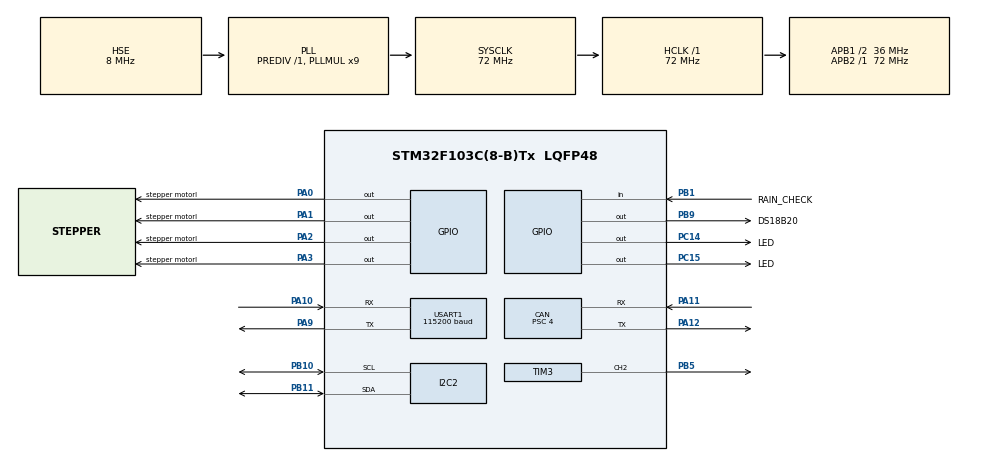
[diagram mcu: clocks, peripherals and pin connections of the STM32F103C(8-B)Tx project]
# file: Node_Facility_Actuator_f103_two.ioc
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CAN.BS1=CAN_BS1_7TQ
CAN.BS2=CAN_BS2_5TQ
CAN.CalculateBaudRate=692307
CAN.CalculateTimeBit=1444
CAN.CalculateTimeQuantum=111.11111111111111
CAN.Prescaler=4
CAN.SJW=CAN_SJW_2TQ
Dma.Request0=USART1_RX
Dma.USART1_RX.0.Direction=DMA_PERIPH_TO_MEMORY
Dma.USART1_RX.0.Instance=DMA1_Channel5
Dma.USART1_RX.0.MemDataAlignment=DMA_MDATAALIGN_BYTE
Dma.USART1_RX.0.MemInc=DMA_MINC_ENABLE
Dma.USART1_RX.0.Mode=DMA_CIRCULAR
Dma.USART1_RX.0.PeriphDataAlignment=DMA_PDATAALIGN_BYTE
Dma.USART1_RX.0.PeriphInc=DMA_PINC_DISABLE
Dma.USART1_RX.0.Priority=DMA_PRIORITY_LOW
FREERTOS.Queues01=Button_Queue,8,uint8_t,0,Dynamic,NULL,NULL
FREERTOS.Tasks01=APP_TASK,40,256,App_Show_Task,As weak,NULL,Dynamic,NULL,NULL;Acquire_Task,8,256,Data_Acquire_Task,As weak,NULL,Dynamic,NULL,NULL;Data_handle,8,256,Deal_data,As weak,NULL,Dynamic,NULL,NULL;Device,8,256,device_control,As weak,NULL,Dynamic,NULL,NULL
FREERTOS.configMINIMAL_STACK_SIZE=256
FREERTOS.configTOTAL_HEAP_SIZE=8192
Mcu.Family=STM32F1
Mcu.Name=STM32F103C(8-B)Tx
Mcu.Package=LQFP48
NVIC.DMA1_Channel5_IRQn=true\:5\:0\:false\:false\:true\:true\:false\:true\:true
NVIC.PriorityGroup=NVIC_PRIORITYGROUP_4
NVIC.TIM4_IRQn=true\:15\:0\:false\:false\:true\:false\:false\:true\:true
NVIC.TimeBase=TIM4_IRQn
NVIC.TimeBaseIP=TIM4
NVIC.USART1_IRQn=true\:5\:0\:false\:false\:false\:true\:true\:true\:true
PA0-WKUP.GPIO_Label=stepper motorl
PA0-WKUP.GPIO_ModeDefaultOutputPP=GPIO_MODE_OUTPUT_PP
PA0-WKUP.GPIO_PuPd=GPIO_NOPULL
PA0-WKUP.GPIO_Speed=GPIO_SPEED_FREQ_MEDIUM
PA0-WKUP.PinState=GPIO_PIN_RESET
PA0-WKUP.Signal=GPIO_Output
PA1.GPIO_Label=stepper motorl
PA1.GPIO_ModeDefaultOutputPP=GPIO_MODE_OUTPUT_PP
PA1.GPIO_PuPd=GPIO_NOPULL
PA1.GPIO_Speed=GPIO_SPEED_FREQ_MEDIUM
PA1.PinState=GPIO_PIN_RESET
PA1.Signal=GPIO_Output
PA10.Mode=Asynchronous
PA10.Signal=USART1_RX
PA11.Mode=CAN_Activate
PA11.Signal=CAN_RX
PA12.Mode=CAN_Activate
PA12.Signal=CAN_TX
PA13.Mode=Serial_Wire
PA13.Signal=SYS_JTMS-SWDIO
PA14.Mode=Serial_Wire
PA14.Signal=SYS_JTCK-SWCLK
PA2.GPIO_Label=stepper motorl
PA2.GPIO_ModeDefaultOutputPP=GPIO_MODE_OUTPUT_PP
PA2.GPIO_PuPd=GPIO_NOPULL
PA2.GPIO_Speed=GPIO_SPEED_FREQ_MEDIUM
PA2.PinState=GPIO_PIN_RESET
PA2.Signal=GPIO_Output
PA3.GPIO_Label=stepper motorl
PA3.GPIO_ModeDefaultOutputPP=GPIO_MODE_OUTPUT_PP
PA3.GPIO_PuPd=GPIO_NOPULL
PA3.GPIO_Speed=GPIO_SPEED_FREQ_MEDIUM
PA3.PinState=GPIO_PIN_RESET
PA3.Signal=GPIO_Output
PA9.Mode=Asynchronous
PA9.Signal=USART1_TX
PB1.GPIO_Label=RAIN_CHECK
PB1.Signal=GPIO_Input
PB10.Mode=I2C
PB10.Signal=I2C2_SCL
PB11.Mode=I2C
PB11.Signal=I2C2_SDA
PB5.Signal=S_TIM3_CH2
PB9.GPIO_Label=DS18B20
PB9.GPIO_ModeDefaultOutputPP=GPIO_MODE_OUTPUT_OD
PB9.GPIO_PuPd=GPIO_NOPULL
PB9.GPIO_Speed=GPIO_SPEED_FREQ_HIGH
PB9.Signal=GPIO_Output
PC14-OSC32_IN.GPIO_Label=LED
PC14-OSC32_IN.GPIO_ModeDefaultOutputPP=GPIO_MODE_OUTPUT_PP
PC14-OSC32_IN.GPIO_PuPd=GPIO_NOPULL
PC14-OSC32_IN.GPIO_Speed=GPIO_SPEED_FREQ_LOW
PC14-OSC32_IN.PinState=GPIO_PIN_SET
PC14-OSC32_IN.Signal=GPIO_Output
PC15-OSC32_OUT.GPIO_Label=LED
PC15-OSC32_OUT.GPIO_ModeDefaultOutputPP=GPIO_MODE_OUTPUT_PP
PC15-OSC32_OUT.GPIO_PuPd=GPIO_NOPULL
PC15-OSC32_OUT.GPIO_Speed=GPIO_SPEED_FREQ_LOW
PC15-OSC32_OUT.PinState=GPIO_PIN_SET
PC15-OSC32_OUT.Signal=GPIO_Output
PD0-OSC_IN.Mode=HSE-External-Oscillator
PD0-OSC_IN.Signal=RCC_OSC_IN
PD1-OSC_OUT.Mode=HSE-External-Oscillator
PD1-OSC_OUT.Signal=RCC_OSC_OUT
ProjectManager.HeapSize=0x200
ProjectManager.StackSize=0x400
ProjectManager.TargetToolchain=CMake
RCC.ADCPresc=RCC_ADCPCLK2_DIV6
RCC.AHBFreq_Value=72000000
RCC.APB1CLKDivider=RCC_HCLK_DIV2
RCC.APB1Freq_Value=36000000
RCC.APB1TimFreq_Value=72000000
RCC.APB2Freq_Value=72000000
RCC.APB2TimFreq_Value=72000000
RCC.HCLKFreq_Value=72000000
RCC.PLLMUL=RCC_PLL_MUL9
RCC.PLLSourceVirtual=RCC_PLLSOURCE_HSE
RCC.SYSCLKFreq_VALUE=72000000
RCC.SYSCLKSource=RCC_SYSCLKSOURCE_PLLCLK
RCC.USBFreq_Value=72000000
SH.S_TIM3_CH2.0=TIM3_CH2,PWM Generation2 CH2
TIM3.Channel-PWM\ Generation2\ CH2=TIM_CHANNEL_2
TIM3.Period=100
TIM3.Prescaler=720
USART1.BaudRate=115200
USART1.VirtualMode=VM_ASYNC
VP_FREERTOS_VS_CMSIS_V2.Mode=CMSIS_V2
VP_SYS_VS_tim4.Mode=TIM4
board=custom

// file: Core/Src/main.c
/* USER CODE BEGIN Header */
/**
  ******************************************************************************
  * @file           : main.c
  * @brief          : Main program body
  ******************************************************************************
  * @attention
  *
  * Copyright (c) 2026 STMicroelectronics.
  * All rights reserved.
  *
  * This software is licensed under terms that can be found in the LICENSE file
  * in the root directory of this software component.
  * If no LICENSE file comes with this software, it is provided AS-IS.
  *
  ******************************************************************************
  */
/* USER CODE END Header */
#include "main.h"
#include "cmsis_os.h"
#include "can.h"
#include "dma.h"
#include "i2c.h"
#include "tim.h"
#include "usart.h"
#include "gpio.h"

/* USER CODE BEGIN Includes */
#include "app_display.h"
/* USER CODE END Includes */

void SystemClock_Config(void);
void MX_FREERTOS_Init(void);

int main(void)
{

  /* MCU Configuration--------------------------------------------------------*/

  /* Reset of all peripherals, Initializes the Flash interface and the Systick. */
  HAL_Init();

  /* Configure the system clock */
  SystemClock_Config();

  /* Initialize all configured peripherals */
  MX_GPIO_Init();
  MX_DMA_Init();
  MX_CAN_Init();
  MX_USART1_UART_Init();
  MX_I2C2_Init();
  MX_TIM3_Init();
  /* USER CODE BEGIN 2 */

//代码初始化的地方！！！
app_init();

  /* USER CODE END 2 */

  /* Init scheduler */
  osKernelInitialize();  /* Call init function for freertos objects (in cmsis_os2.c) */
  MX_FREERTOS_Init();

  /* Start scheduler */
  osKernelStart();

  /* We should never get here as control is now taken by the scheduler */

  /* Infinite loop */
  while (1)
  {

  }
}

void SystemClock_Config(void)
{
  RCC_OscInitTypeDef RCC_OscInitStruct = {0};
  RCC_ClkInitTypeDef RCC_ClkInitStruct = {0};

  /** Initializes the RCC Oscillators according to the specified parameters
  * in the RCC_OscInitTypeDef structure.
  */
  RCC_OscInitStruct.OscillatorType = RCC_OSCILLATORTYPE_HSE;
  RCC_OscInitStruct.HSEState = RCC_HSE_ON;
  RCC_OscInitStruct.HSEPredivValue = RCC_HSE_PREDIV_DIV1;
  RCC_OscInitStruct.HSIState = RCC_HSI_ON;
  RCC_OscInitStruct.PLL.PLLState = RCC_PLL_ON;
  RCC_OscInitStruct.PLL.PLLSource = RCC_PLLSOURCE_HSE;
  RCC_OscInitStruct.PLL.PLLMUL = RCC_PLL_MUL9;
  if (HAL_RCC_OscConfig(&RCC_OscInitStruct) != HAL_OK)
  {
    Error_Handler();
  }

  /** Initializes the CPU, AHB and APB buses clocks
  */
  RCC_ClkInitStruct.ClockType = RCC_CLOCKTYPE_HCLK|RCC_CLOCKTYPE_SYSCLK
                              |RCC_CLOCKTYPE_PCLK1|RCC_CLOCKTYPE_PCLK2;
  RCC_ClkInitStruct.SYSCLKSource = RCC_SYSCLKSOURCE_PLLCLK;
  RCC_ClkInitStruct.AHBCLKDivider = RCC_SYSCLK_DIV1;
  RCC_ClkInitStruct.APB1CLKDivider = RCC_HCLK_DIV2;
  RCC_ClkInitStruct.APB2CLKDivider = RCC_HCLK_DIV1;

  if (HAL_RCC_ClockConfig(&RCC_ClkInitStruct, FLASH_LATENCY_2) != HAL_OK)
  {
    Error_Handler();
  }
}

void HAL_TIM_PeriodElapsedCallback(TIM_HandleTypeDef *htim)
{
  if (htim->Instance == TIM4)
  {
    HAL_IncTick();
  }
}

void Error_Handler(void)
{
  __disable_irq();
  while (1)
  {
  }
}

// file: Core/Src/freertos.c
/* USER CODE BEGIN Header */
/**
  ******************************************************************************
  * File Name          : freertos.c
  * Description        : Code for freertos applications
  ******************************************************************************
  * @attention
  *
  * Copyright (c) 2026 STMicroelectronics.
  * All rights reserved.
  *
  * This software is licensed under terms that can be found in the LICENSE file
  * in the root directory of this software component.
  * If no LICENSE file comes with this software, it is provided AS-IS.
  *
  ******************************************************************************
  */
/* USER CODE END Header */

#include "FreeRTOS.h"
#include "task.h"
#include "main.h"
#include "cmsis_os.h"

/* Definitions for APP_TASK */
osThreadId_t APP_TASKHandle;
const osThreadAttr_t APP_TASK_attributes = {
  .name = "APP_TASK",
  .stack_size = 256 * 4,
  .priority = (osPriority_t) osPriorityHigh,
};
/* Definitions for Acquire_Task */
osThreadId_t Acquire_TaskHandle;
const osThreadAttr_t Acquire_Task_attributes = {
  .name = "Acquire_Task",
  .stack_size = 256 * 4,
  .priority = (osPriority_t) osPriorityLow,
};
/* Definitions for Data_handle */
osThreadId_t Data_handleHandle;
const osThreadAttr_t Data_handle_attributes = {
  .name = "Data_handle",
  .stack_size = 256 * 4,
  .priority = (osPriority_t) osPriorityLow,
};
/* Definitions for Device */
osThreadId_t DeviceHandle;
const osThreadAttr_t Device_attributes = {
  .name = "Device",
  .stack_size = 256 * 4,
  .priority = (osPriority_t) osPriorityLow,
};
/* Definitions for Button_Queue */
osMessageQueueId_t Button_QueueHandle;
const osMessageQueueAttr_t Button_Queue_attributes = {
  .name = "Button_Queue"
};

void App_Show_Task(void *argument);
void Data_Acquire_Task(void *argument);
void Deal_data(void *argument);
void device_control(void *argument);

void MX_FREERTOS_Init(void); /* (MISRA C 2004 rule 8.1) */

void MX_FREERTOS_Init(void) {

  /* Create the queue(s) */
  /* creation of Button_Queue */
  Button_QueueHandle = osMessageQueueNew (8, sizeof(uint8_t), &Button_Queue_attributes);

  /* Create the thread(s) */
  /* creation of APP_TASK */
  APP_TASKHandle = osThreadNew(App_Show_Task, NULL, &APP_TASK_attributes);

  /* creation of Acquire_Task */
  Acquire_TaskHandle = osThreadNew(Data_Acquire_Task, NULL, &Acquire_Task_attributes);

  /* creation of Data_handle */
  Data_handleHandle = osThreadNew(Deal_data, NULL, &Data_handle_attributes);

  /* creation of Device */
  DeviceHandle = osThreadNew(device_control, NULL, &Device_attributes);

}

__weak void App_Show_Task(void *argument)
{
  for(;;)
  {
    osDelay(1);
  }
}

__weak void Data_Acquire_Task(void *argument)
{
  for(;;)
  {
    osDelay(1);
  }
}

__weak void Deal_data(void *argument)
{
  for(;;)
  {
    osDelay(1);
  }
}

__weak void device_control(void *argument)
{
  for(;;)
  {
    osDelay(1);
  }
}
